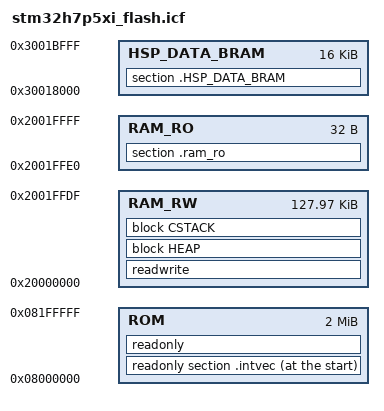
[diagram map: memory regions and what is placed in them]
/**
******************************************************************************
* @file    stm32h7p5xi_flash.icf
* @brief   Linker File
******************************************************************************
* @attention
*
* Copyright (c) 2026 STMicroelectronics.
* All rights reserved.
*
* This software is licensed under terms that can be found in the LICENSE file
* in the root directory of this software component.
* If no LICENSE file comes with this software, it is provided AS-IS.
*
******************************************************************************
*/

define memory mem with size = 4G;
define region ROM = mem:[from 0x8000000 size 0x200000];
define region RAM_RW = mem:[from 0x20000000 size 0x1FFE0];
define region RAM_RO = mem:[from 0x2001FFE0 size 0x20];
define region HSP_DATA_BRAM = mem:[from 0x30018000 size 0x4000];

/* define blocks */
define block HEAP with alignment = 8, size = 0x200 { };
define block CSTACK with alignment = 8, size = 0x400 { };

/* setup initialization strategies */
initialize by copy {
  readwrite
};

do not initialize {
  section .noinit,
  section .HSP_DATA_BRAM
};

place at start of ROM { readonly section .intvec } ;

/* sections placements */
place in ROM {
  readonly
};

place in RAM_RW {
  readwrite,
  block HEAP,
  block CSTACK
};

place in RAM_RO {
   section .ram_ro
};

place in HSP_DATA_BRAM {
  section .HSP_DATA_BRAM
};
